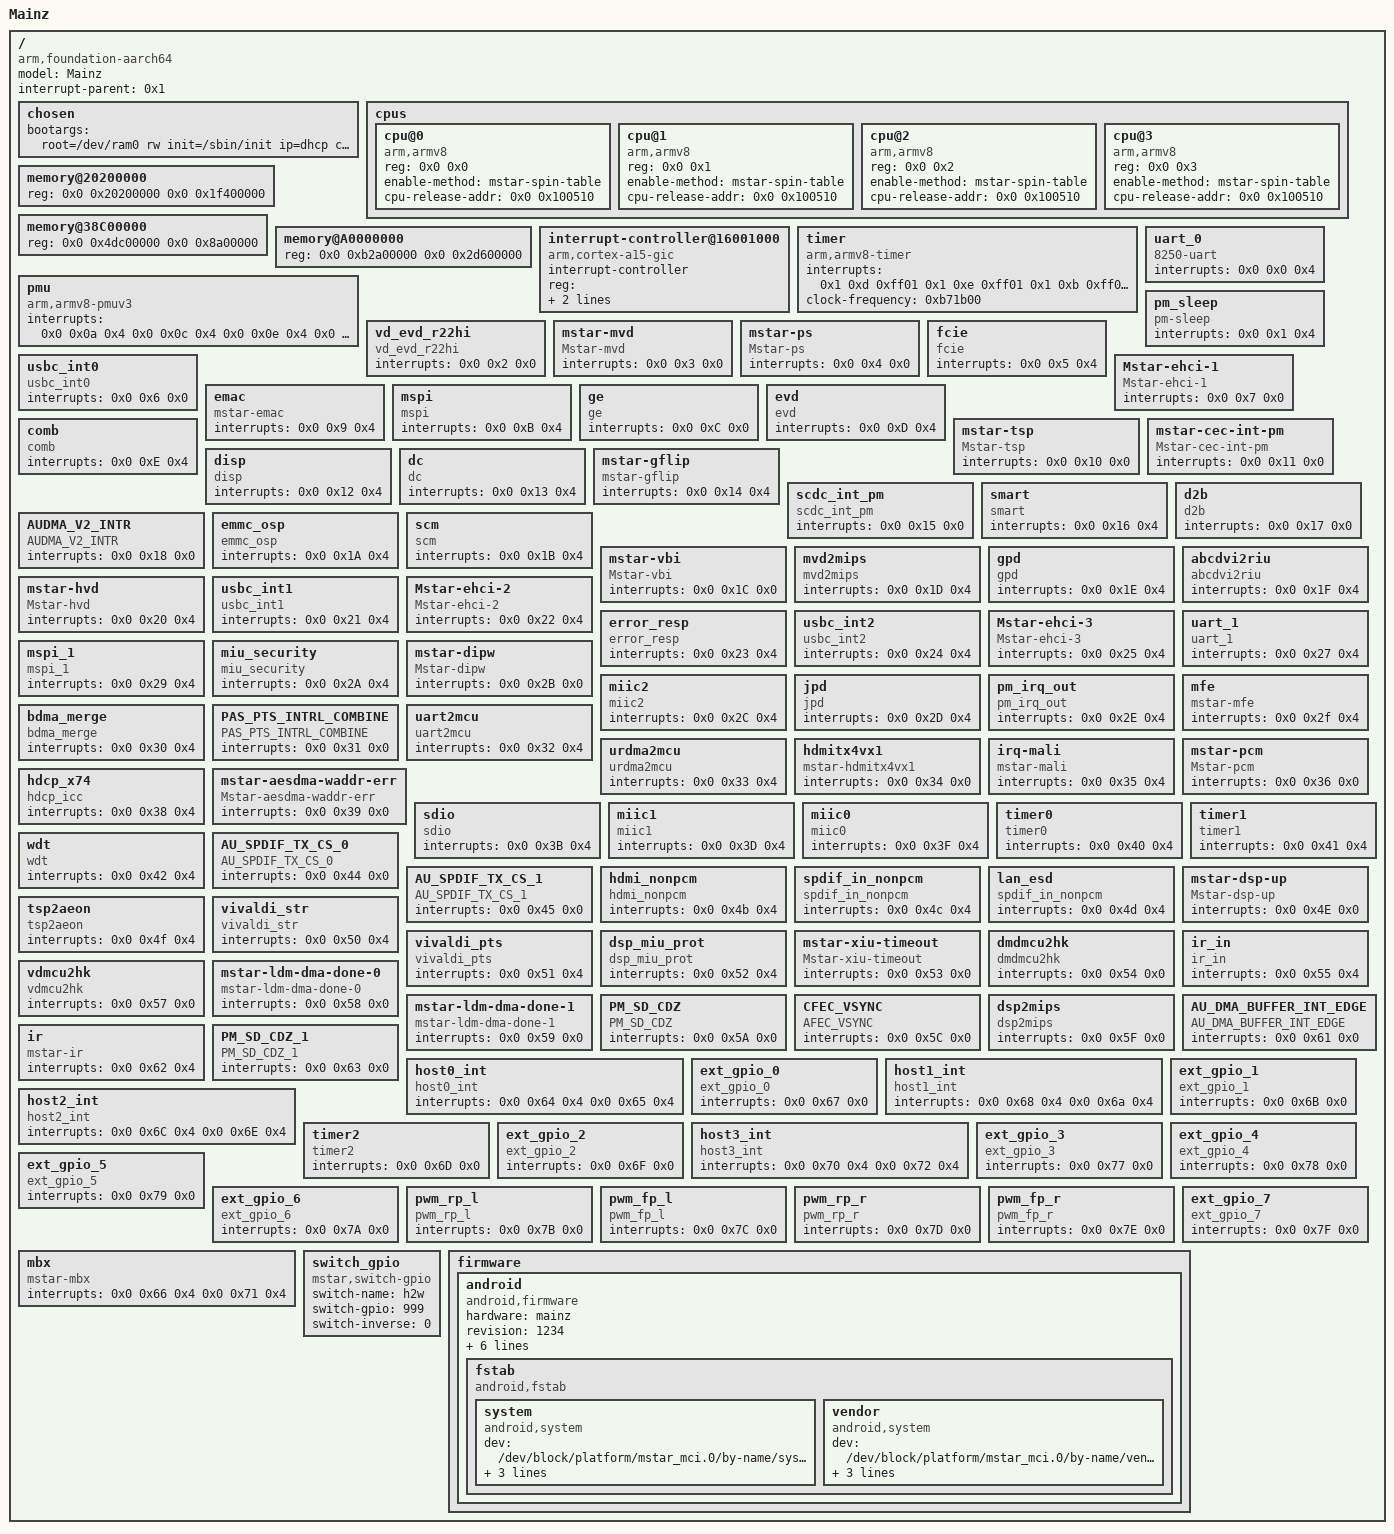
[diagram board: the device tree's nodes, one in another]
/dts-v1/;

/ {
	model = "Mainz";
	compatible = "arm,foundation-aarch64", "arm,mainz";
	interrupt-parent = <0x1>;
	#address-cells = <0x2>;
	#size-cells = <0x2>;

	chosen {
		bootargs = "root=/dev/ram0 rw init=/sbin/init ip=dhcp console=ttyS0,115200,LX_MEM=0x02000000 CMA0=mali0,miu=0,hid=16,sz=0x19000000 CMA1=mali1,miu=1,hid=17,sz=0x5400000 CORE_DUMP_PATH=/mnt/usb/core_dump.%%p.gz AN_VERSION=6_0";
	};

	cpus {
		#address-cells = <0x2>;
		#size-cells = <0x0>;

		cpu@0 {
			device_type = "cpu";
			compatible = "arm,armv8";
			reg = <0x0 0x0>;
			enable-method = "mstar-spin-table";
			cpu-release-addr = <0x0 0x100510>;
		};

		cpu@1 {
			device_type = "cpu";
			compatible = "arm,armv8";
			reg = <0x0 0x1>;
			enable-method = "mstar-spin-table";
			cpu-release-addr = <0x0 0x100510>;
		};

		cpu@2 {
			device_type = "cpu";
			compatible = "arm,armv8";
			reg = <0x0 0x2>;
			enable-method = "mstar-spin-table";
			cpu-release-addr = <0x0 0x100510>;
		};

		cpu@3 {
			device_type = "cpu";
			compatible = "arm,armv8";
			reg = <0x0 0x3>;
			enable-method = "mstar-spin-table";
			cpu-release-addr = <0x0 0x100510>;
		};
	};

	memory@20200000 {
		device_type = "memory";
		reg = <0x0 0x20200000 0x0 0x1f400000>;
	};

	memory@38C00000 {
		device_type = "memory";
		reg = <0x0 0x4dc00000 0x0 0x8a00000>;
	};

	memory@A0000000 {
		device_type = "memory";
		reg = <0x0 0xb2a00000 0x0 0x2d600000>;
	};

	interrupt-controller@16001000 {
		compatible = "arm,cortex-a15-gic", "arm,cortex-a9-gic";
		#interrupt-cells = <0x3>;
		#address-cells = <0x0>;
		interrupt-controller;
		reg = <0x0 0x16001000 0x0 0x1000 0x0 0x16002000 0x0 0x4000>;
		interrupts = <0x1 0x9 0xf04>;
		linux,phandle = <0x1>;
		phandle = <0x1>;
	};

	timer {
		compatible = "arm,armv8-timer";
		interrupts = <0x1 0xd 0xff01 0x1 0xe 0xff01 0x1 0xb 0xff01 0x1 0xa 0xff01>;
		clock-frequency = <0xb71b00>;
	};

	pmu {
		compatible = "arm,armv8-pmuv3";
		interrupts = <0x0 0x0a 0x4 0x0 0x0c 0x4 0x0 0x0e 0x4 0x0 0x10 0x4>;
	};

	uart_0 {
		compatible = "8250-uart";
		interrupts = <0x0 0x0 0x4>;
	};

	pm_sleep {
		compatible = "pm-sleep";
		interrupts = <0x0 0x1 0x4>;
	};

	vd_evd_r22hi {
		compatible = "vd_evd_r22hi";
		interrupts = <0x0 0x2 0x0>;
	};

	mstar-mvd {
		compatible = "Mstar-mvd";
		interrupts = <0x0 0x3 0x0>;
	};

	mstar-ps {
		compatible = "Mstar-ps";
		interrupts = <0x0 0x4 0x0>;
	};

	fcie {
		compatible = "fcie";
		interrupts = <0x0 0x5 0x4>;
	};

	usbc_int0 {
		compatible = "usbc_int0";
		interrupts = <0x0 0x6 0x0>;
	};

	Mstar-ehci-1 {
		compatible = "Mstar-ehci-1";
		interrupts = <0x0 0x7 0x0>;
	};

	emac {
		compatible = "mstar-emac";
		interrupts = <0x0 0x9 0x4>;
	};
	
	mspi {
		compatible = "mspi";
		interrupts = <0x0 0xB 0x4>;
	};

	ge {
		compatible = "ge";
		interrupts = <0x0 0xC 0x0>;
	};

	evd {
		compatible = "evd";
		interrupts = <0x0 0xD 0x4>;
	};

	comb {
		compatible = "comb";
		interrupts = <0x0 0xE 0x4>;
	};

	mstar-tsp {
		compatible = "Mstar-tsp";
		interrupts = <0x0 0x10 0x0>;
	};
	
	mstar-cec-int-pm {
		compatible = "Mstar-cec-int-pm";
		interrupts = <0x0 0x11 0x0>;
	};

	disp{
		compatible = "disp";
		interrupts = <0x0 0x12 0x4>;
	};
	
	dc {
		compatible = "dc";
		interrupts = <0x0 0x13 0x4>;
	};

	mstar-gflip {
		compatible = "mstar-gflip";
		interrupts = <0x0 0x14 0x4>;
	};
	
	scdc_int_pm {
		compatible = "scdc_int_pm";
		interrupts = <0x0 0x15 0x0>;
	};

	smart {
		compatible = "smart";
		interrupts = <0x0 0x16 0x4>;
	};
	
	d2b {
		compatible = "d2b";
		interrupts = <0x0 0x17 0x0>;
	};
	
	AUDMA_V2_INTR {
		compatible = "AUDMA_V2_INTR";
		interrupts = <0x0 0x18 0x0>;
	};
	
	emmc_osp {
		compatible = "emmc_osp";
		interrupts = <0x0 0x1A 0x4>;
	};
	
	scm {
		compatible = "scm";
		interrupts = <0x0 0x1B 0x4>;
	};

	mstar-vbi {
		compatible = "Mstar-vbi";
		interrupts = <0x0 0x1C 0x0>;
	};
	
	mvd2mips {
		compatible = "mvd2mips";
		interrupts = <0x0 0x1D 0x4>;
	};
	
	gpd {
		compatible = "gpd";
		interrupts = <0x0 0x1E 0x4>;
	};

	abcdvi2riu {
		compatible = "abcdvi2riu";
		interrupts = <0x0 0x1F 0x4>;
	};

	mstar-hvd {
		compatible = "Mstar-hvd";
		interrupts = <0x0 0x20 0x4>;
	};

	usbc_int1 {
		compatible = "usbc_int1";
		interrupts = <0x0 0x21 0x4>;
	};

	Mstar-ehci-2 {
		compatible = "Mstar-ehci-2";
		interrupts = <0x0 0x22 0x4>;
	};

	error_resp {
		compatible = "error_resp";
		interrupts = <0x0 0x23 0x4>;
	};

	usbc_int2 {
		compatible = "usbc_int2";
		interrupts = <0x0 0x24 0x4>;
	};

	Mstar-ehci-3 {
		compatible = "Mstar-ehci-3";
		interrupts = <0x0 0x25 0x4>;
	};
	
	uart_1 {
		compatible = "uart_1";
		interrupts = <0x0 0x27 0x4>;
	};

	mspi_1 {
		compatible = "mspi_1";
		interrupts = <0x0 0x29 0x4>;
	};

	miu_security {
		compatible = "miu_security";
		interrupts = <0x0 0x2A 0x4>;
	};

	mstar-dipw {
		compatible = "Mstar-dipw";
		interrupts = <0x0 0x2B 0x0>;
	};

	miic2 {
		compatible = "miic2";
		interrupts = <0x0 0x2C 0x4>;
	};

	jpd {
		compatible = "jpd";
		interrupts = <0x0 0x2D 0x4>;
	};

	pm_irq_out {
		compatible = "pm_irq_out";
		interrupts = <0x0 0x2E 0x4>;
	};

	mfe {
		compatible = "mstar-mfe";
		interrupts = <0x0 0x2f 0x4>;
	};

	bdma_merge {
		compatible = "bdma_merge";
		interrupts = <0x0 0x30 0x4>;
	};
	
	PAS_PTS_INTRL_COMBINE {
		compatible = "PAS_PTS_INTRL_COMBINE";
		interrupts = <0x0 0x31 0x0>;
	};

	uart2mcu {
		compatible = "uart2mcu";
		interrupts = <0x0 0x32 0x4>;
	};

	urdma2mcu {
		compatible = "urdma2mcu";
		interrupts = <0x0 0x33 0x4>;
	};

	hdmitx4vx1 {
		compatible = "mstar-hdmitx4vx1";
		interrupts = <0x0 0x34 0x0>;
	};

	irq-mali {
		compatible = "mstar-mali";
		interrupts = <0x0 0x35 0x4>;
	};
				
	mstar-pcm {
		compatible = "Mstar-pcm";
		interrupts = <0x0 0x36 0x0>;
	};

	
	hdcp_x74 {
		compatible = "hdcp_icc";
		interrupts = <0x0 0x38 0x4>;
	};

	mstar-aesdma-waddr-err {
		compatible = "Mstar-aesdma-waddr-err";
		interrupts = <0x0 0x39 0x0>;
	};

	sdio {
		compatible = "sdio";
		interrupts = <0x0 0x3B 0x4>;
	};

	miic1 {
		compatible = "miic1";
		interrupts = <0x0 0x3D 0x4>;
	};

	miic0 {
		compatible = "miic0";
		interrupts = <0x0 0x3F 0x4>;
	};

	timer0 {
		compatible = "timer0";
		interrupts = <0x0 0x40 0x4>;
	};

	timer1 {
		compatible = "timer1";
		interrupts = <0x0 0x41 0x4>;
	};

	wdt {
		compatible = "wdt";
		interrupts = <0x0 0x42 0x4>;
	};
		
	AU_SPDIF_TX_CS_0 {
		compatible = "AU_SPDIF_TX_CS_0";
		interrupts = <0x0 0x44 0x0>;
	};

	AU_SPDIF_TX_CS_1 {
		compatible = "AU_SPDIF_TX_CS_1";
		interrupts = <0x0 0x45 0x0>;
	};

    hdmi_nonpcm {
        compatible = "hdmi_nonpcm";
        interrupts = <0x0 0x4b 0x4>;
    };

    spdif_in_nonpcm {
        compatible = "spdif_in_nonpcm";
        interrupts = <0x0 0x4c 0x4>;
    };

    lan_esd {
        compatible = "spdif_in_nonpcm";
        interrupts = <0x0 0x4d 0x4>;
    };

	mstar-dsp-up {
		compatible = "Mstar-dsp-up";
		interrupts = <0x0 0x4E 0x0>;
	};

    tsp2aeon {
        compatible = "tsp2aeon";
        interrupts = <0x0 0x4f 0x4>;
    };

    vivaldi_str {
        compatible = "vivaldi_str";
        interrupts = <0x0 0x50 0x4>;
    };

    vivaldi_pts {
        compatible = "vivaldi_pts";
        interrupts = <0x0 0x51 0x4>;
    };

    dsp_miu_prot {
        compatible = "dsp_miu_prot";
        interrupts = <0x0 0x52 0x4>;
    };

	mstar-xiu-timeout {
		compatible = "Mstar-xiu-timeout";
		interrupts = <0x0 0x53 0x0>;
	};

    dmdmcu2hk {
        compatible = "dmdmcu2hk";
        interrupts = <0x0 0x54 0x0>;
    };
	
	ir_in {
		compatible = "ir_in";
		interrupts = <0x0 0x55 0x4>;
	};

	vdmcu2hk {
		compatible = "vdmcu2hk";
		interrupts = <0x0 0x57 0x0>;
	};

	mstar-ldm-dma-done-0 {
		compatible = "mstar-ldm-dma-done-0";
		interrupts = <0x0 0x58 0x0>;
	};

	mstar-ldm-dma-done-1 {
		compatible = "mstar-ldm-dma-done-1";
		interrupts = <0x0 0x59 0x0>;
	};

	PM_SD_CDZ {
		compatible = "PM_SD_CDZ";
		interrupts = <0x0 0x5A 0x0>;
	};

	CFEC_VSYNC {
		compatible = "AFEC_VSYNC";
		interrupts = <0x0 0x5C 0x0>;
	};
	

	dsp2mips {
		compatible = "dsp2mips";
		interrupts = <0x0 0x5F 0x0>;
	};
	AU_DMA_BUFFER_INT_EDGE {
		compatible = "AU_DMA_BUFFER_INT_EDGE";
		interrupts = <0x0 0x61 0x0>;
	};

	ir {
		compatible = "mstar-ir";
		interrupts = <0x0 0x62 0x4>;
	};

	PM_SD_CDZ_1 {
		compatible = "PM_SD_CDZ_1";
		interrupts = <0x0 0x63 0x0>;
	};

	host0_int {
		compatible = "host0_int";
		interrupts = <0x0 0x64 0x4  0x0 0x65 0x4>;
	};

	ext_gpio_0 {
		compatible = "ext_gpio_0";
		interrupts = <0x0 0x67 0x0>;
	};

	host1_int {
		compatible = "host1_int";
		interrupts = <0x0 0x68 0x4  0x0 0x6a 0x4>;
	};

	ext_gpio_1 {
		compatible = "ext_gpio_1";
		interrupts = <0x0 0x6B 0x0>;
	};

	host2_int {
		compatible = "host2_int";
		interrupts = <0x0 0x6C 0x4  0x0 0x6E 0x4>;
	};

	timer2 {
		compatible = "timer2";
		interrupts = <0x0 0x6D 0x0>;
	};

	ext_gpio_2 {
		compatible = "ext_gpio_2";
		interrupts = <0x0 0x6F 0x0>;
	};

	host3_int {
		compatible = "host3_int";
		interrupts = <0x0 0x70 0x4  0x0 0x72 0x4>;
	};

	ext_gpio_3 {
		compatible = "ext_gpio_3";
		interrupts = <0x0 0x77 0x0>;
	};

	ext_gpio_4 {
		compatible = "ext_gpio_4";
		interrupts = <0x0 0x78 0x0>;
	};

	ext_gpio_5 {
		compatible = "ext_gpio_5";
		interrupts = <0x0 0x79 0x0>;
	};

	ext_gpio_6 {
		compatible = "ext_gpio_6";
		interrupts = <0x0 0x7A 0x0>;
	};

	pwm_rp_l {
		compatible = "pwm_rp_l";
		interrupts = <0x0 0x7B 0x0>;
	};

	pwm_fp_l {
		compatible = "pwm_fp_l";
		interrupts = <0x0 0x7C 0x0>;
	};

	pwm_rp_r {
		compatible = "pwm_rp_r";
		interrupts = <0x0 0x7D 0x0>;
	};

	pwm_fp_r {
		compatible = "pwm_fp_r";
		interrupts = <0x0 0x7E 0x0>;
	};

	ext_gpio_7 {
		compatible = "ext_gpio_7";
		interrupts = <0x0 0x7F 0x0>;
	};

	mbx {
		compatible = "mstar-mbx";
		interrupts = <0x0 0x66 0x4  0x0 0x71 0x4>;
	};

	switch_gpio {
		compatible = "mstar,switch-gpio";
		switch-name = "h2w";
		switch-gpio = <999>;
		switch-inverse = <0>;
	};

	firmware {

		android {
			compatible = "android,firmware";
			hardware = "mainz";
			revision = "1234";
			Serial = "0000000000000000";
			Processor = "AArch64 Processor rev 3 (aarch64)";
			serialno = "123456789";
			mode = "123456789";
			baseband = "123456789";
			bootloader = "123456789";
			fstab {
				compatible = "android,fstab";
				system {
					compatible = "android,system";
					dev = "/dev/block/platform/mstar_mci.0/by-name/system";
					type = "ext4";
					mnt_flags = "ro";
					fsmgr_flags = "wait";
				};
				vendor {
					compatible = "android,system";
					dev = "/dev/block/platform/mstar_mci.0/by-name/vendor";
					type = "ext4";
					mnt_flags = "ro";
					fsmgr_flags = "wait";
				};
			};
		};
	};
};
